# CH32V407 register map
Vendor: WCH Ltd.; File version: 1.0
Registers are 32-bit, read-write, reset 0x0 unless marked. A register's access mark holds for its fields unless they carry their own. Offsets are from the block's base; [hi:lo] are bit positions; 'fields as' and 'values as' point back to an identical list.

## I3C — Improved inter-integrated circuit
Base 0x40024C00
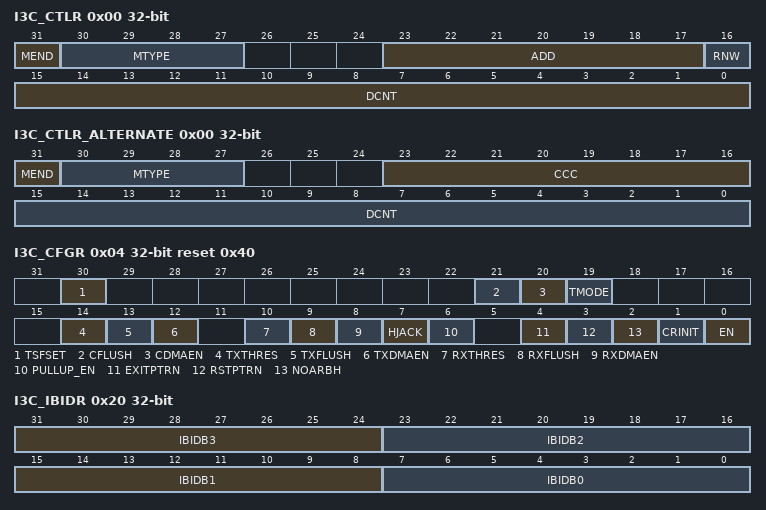
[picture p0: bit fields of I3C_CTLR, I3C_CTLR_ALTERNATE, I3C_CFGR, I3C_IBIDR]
0x00 I3C_CTLR wo — I3C control register
  [31] MEND — message end type
  [30:27] MTYPE — message type
  [23:17] ADD — 7-bit I3C dynamic / I2C static slave address (when I3C is acting as master)
  [16] RNW — read / non-write message (when I3C is acting as master)
  [15:0] DCNT — count of data to transfer during a read or write message, in bytes (whatever I3C is acting as master) Linear encoding up to 64 Kbytes -1
0x00 I3C_CTLR_ALTERNATE wo (alternate view of I3C_CTLR) — I3C message control register alternate
  [31] MEND — message end type (when I3C is acting as master)
  [30:27] MTYPE — message type (when I3C is acting as master)
  [23:16] CCC — 8-bit CCC code
  [15:0] DCNT — count of data to transfer during a read or write message, in bytes Linear encoding up to 64 Kbytes -1....
0x04 I3C_CFGR access per field reset 0x40 — I3C configuration register
  [30] TSFSET wo — frame transfer set (a.k.a. software trigger)
  [21] CFLUSH wo — C-FIFO flush
  [20] CDMAEN rw — C-FIFO DMA request enable
  [19] TMODE rw — transmit mode
  [14] TXTHRES rw — TX-FIFO threshold
  [13] TXFLUSH wo — TX-FIFO flush
  [12] TXDMAEN rw — TX-FIFO DMA request enable
  [10] RXTHRES rw — RX-FIFO threshold
  [9] RXFLUSH wo — RX-FIFO flush ,This bit can only be written.
  [8] RXDMAEN rw — RX-FIFO DMA request enable
  [7] HJACK rw — Hot Join request acknowledge
  [6] PULLUP_EN rw — SDA pull-up enable
  [4] EXITPTRN rw — HDR Exit Pattern enable
  [3] RSTPTRN rw — HDR reset pattern enable
  [2] NOARBH rw — no arbitrable header after a START
  [1] CRINIT rw — initial master/slave role
  [0] EN rw — I3C enable
0x10 I3C_RDR ro — I3C receive data byte register
  [7:0] RDB0 — 8-bit received data on I3C bus.
0x18 I3C_TDR wo — I3C transmit data byte register
  [7:0] TDB0 — 8-bit data to transmit on I3C bus.
0x20 I3C_IBIDR — I3C IBI payload data register
  [31:24] IBIDB3 — 8-bit IBI payload data (latest byte on I3C bus).
  [23:16] IBIDB2 — 8-bit IBI payload data (next byte on I3C bus after IBIDB1[7:0]).
  [15:8] IBIDB1 — 8-bit IBI payload data (next byte on I3C bus after IBIDB0[7:0]).
  [7:0] IBIDB0 — 8-bit IBI payload data (earliest byte on I3C bus, i.e. MDB[7:0] mandatory data byte).
0x2C I3C_RESET reset 0x3000000
  [24] HST_SIE_RST — Reset Register of the Master
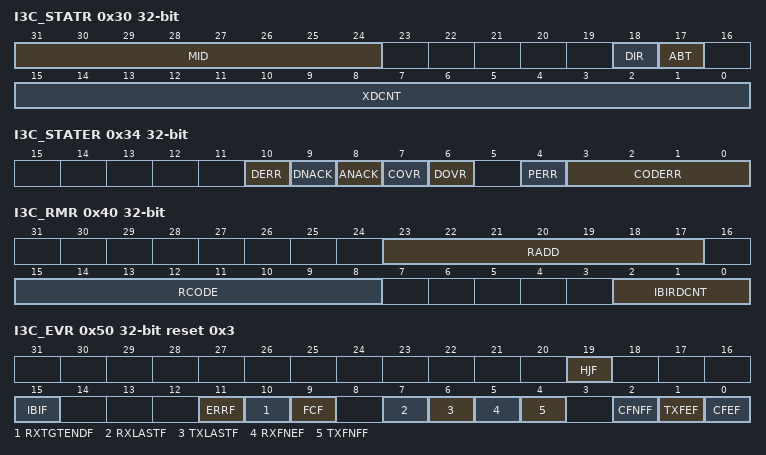
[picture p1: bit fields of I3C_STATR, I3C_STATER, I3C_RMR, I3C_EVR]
0x30 I3C_STATR ro — I3C status register
  [31:24] MID — message identifier/counter of a given frame
  [18] DIR — message direction
  [17] ABT — a private read message is completed/aborted prematurely by the slave
  [15:0] XDCNT — data counter
0x34 I3C_STATER ro — I3C status error register
  [10] DERR — data error
  [9] DNACK — data not acknowledged
  [8] ANACK — address not acknowledged (when the I3C is configured as master)
  [7] COVR — C-FIFO underrun or S-FIFO overrun
  [6] DOVR — RX-FIFO overrun or TX-FIFO underrun
  [4] PERR — protocol error
  [3:0] CODERR — protocol error code/type
0x40 I3C_RMR ro — I3C received message register
  [23:17] RADD — received slave address (when the I3C is configured as master)
  [15:8] RCODE — received CCC code
  [2:0] IBIRDCNT — IBI received payload data count (when the I3C is configured as master)
0x50 I3C_EVR ro reset 0x3 — I3C event register
  [19] HJF — hot-join flag
  [15] IBIF — IBI flag
  [11] ERRF — flag
  [10] RXTGTENDF — slave-initiated read end flag
  [9] FCF — frame complete flag
  [7] RXLASTF — last read data byte/word flag
  [6] TXLASTF — last written data byte/word flag
  [5] RXFNEF — RX-FIFO not empty flag
  [4] TXFNFF — TX-FIFO not full flag
  [2] CFNFF — C-FIFO not full flag
  [1] TXFEF — TX-FIFO empty flag
  [0] CFEF — C-FIFO empty flag
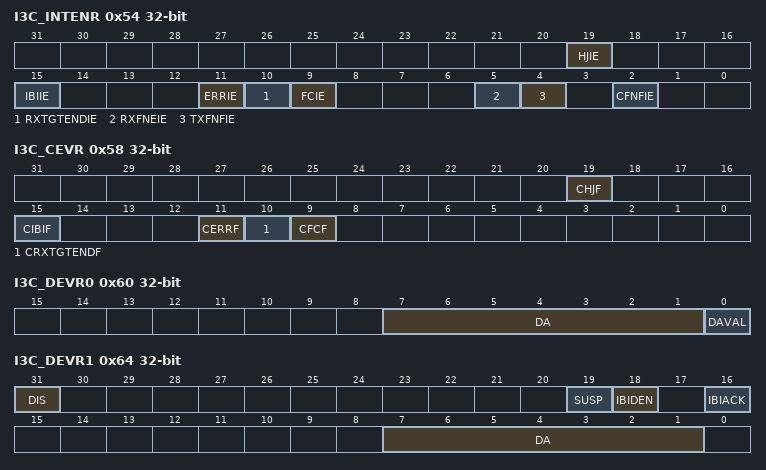
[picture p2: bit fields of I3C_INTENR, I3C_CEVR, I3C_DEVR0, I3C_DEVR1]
0x54 I3C_INTENR ro — I3C interrupt enable register
  [19] HJIE — hot-join interrupt enable
  [15] IBIIE — IBI request interrupt enable
  [11] ERRIE — error interrupt enable (whatever the I3C is acting as master)
  [10] RXTGTENDIE — slave-initiated read end interrupt enable
  [9] FCIE — frame complete interrupt enable
  [5] RXFNEIE — RX-FIFO not empty interrupt enable
  [4] TXFNFIE — TX-FIFO not full interrupt enable
  [2] CFNFIE — C-FIFO not full interrupt enable
0x58 I3C_CEVR wo — I3C clear event register
  [19] CHJF — clear hot-join flag
  [15] CIBIF — clear IBI request flag
  [11] CERRF — clear error flag
  [10] CRXTGTENDF — clear slave-initiated read end flag
  [9] CFCF — clear frame complete flag
0x60 I3C_DEVR0 — I3C own device characteristics register
  [7:1] DA — 7-bit dynamic address
  [0] DAVAL — dynamic address is valid (when the I3C is acting as slave)
0x64 I3C_DEVR1 access per field — I3C device 1 characteristics register
  [31] DIS ro — DA[6:0] write disabled
  [19] SUSP rw — suspend/stop I3C transfer on received IBI
  [18] IBIDEN rw — IBI data enable
  [16] IBIACK rw — IBI request acknowledge
  [7:1] DA rw — assigned I3C dynamic address to slave x
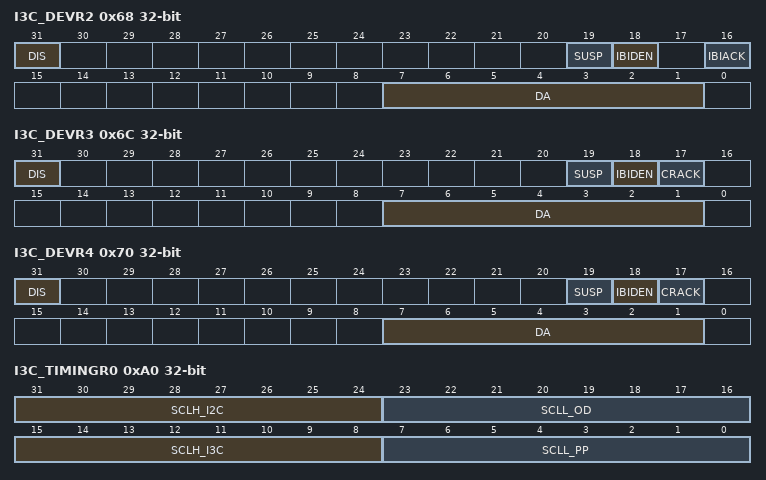
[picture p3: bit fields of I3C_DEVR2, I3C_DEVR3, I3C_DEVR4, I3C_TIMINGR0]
0x68 I3C_DEVR2 access per field — I3C device 2 characteristics register
  fields as I3C_DEVR1
0x6C I3C_DEVR3 access per field — I3C device 3 characteristics register
  [31] DIS ro — DA[6:0] write disabled
  [19] SUSP rw — suspend/stop I3C transfer on received IBI
  [18] IBIDEN rw — IBI data enable
  [17] CRACK rw — master-role request acknowledge
  [7:1] DA rw — assigned I3C dynamic address to slave x
0x70 I3C_DEVR4 access per field — I3C device 4 characteristics register
  fields as I3C_DEVR3
0xA0 I3C_TIMINGR0 — I3C timing register 0
  [31:24] SCLH_I2C — SCL high duration, used for legacy I2C commands, in number of kernel clocks cycles
  [23:16] SCLL_OD — SCL low duration in open-drain phases, used for legacy I2C commands and for I3C open-drain phases (address header phase following a START, not a Repeated START), in number of kernel clocks cycles
  [15:8] SCLH_I3C — SCL high duration, used for I3C messages (both in push-pull and open-drain phases), in number of kernel clocks cycles
  [7:0] SCLL_PP — SCL low duration in I3C push-pull phases, in number of kernel clocks cycles
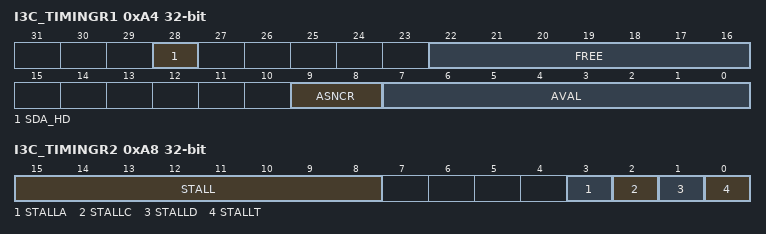
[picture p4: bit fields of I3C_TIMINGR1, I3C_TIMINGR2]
0xA4 I3C_TIMINGR1 — I3C timing register 1
  [28] SDA_HD — SDA hold time, in number of kernel clocks cycles (refer to MIPI timing SDA hold time in push-pull tHD_PP):
  [22:16] FREE — number of kernel clocks cycles that is used to set some MIPI timings like bus free condition time
  [9:8] ASNCR — activity state of the new master (when I3C is acting as active- master)
  [7:0] AVAL — number of kernel clock cycles, that is used whatever I3C is acting as controller or slave, to set the following MIPI I3C timings, like bus available condition time: When the I3C is acting as slave
0xA8 I3C_TIMINGR2 — I3C timing register 2
  [15:8] STALL — master clock stall time, in number of kernel clock cycles
  [3] STALLA — master clock stall enable on ACK phase
  [2] STALLC — master clock stall on PAR phase of CCC enable
  [1] STALLD — master clock stall on PAR phase of Data enable
  [0] STALLT — master clock stall on T-bit phase of Data enable
0xD0 I3C_GETMDSR — I3C get capability register
  [24] TSCO — clock-to-data turnaround time (tSCO)
